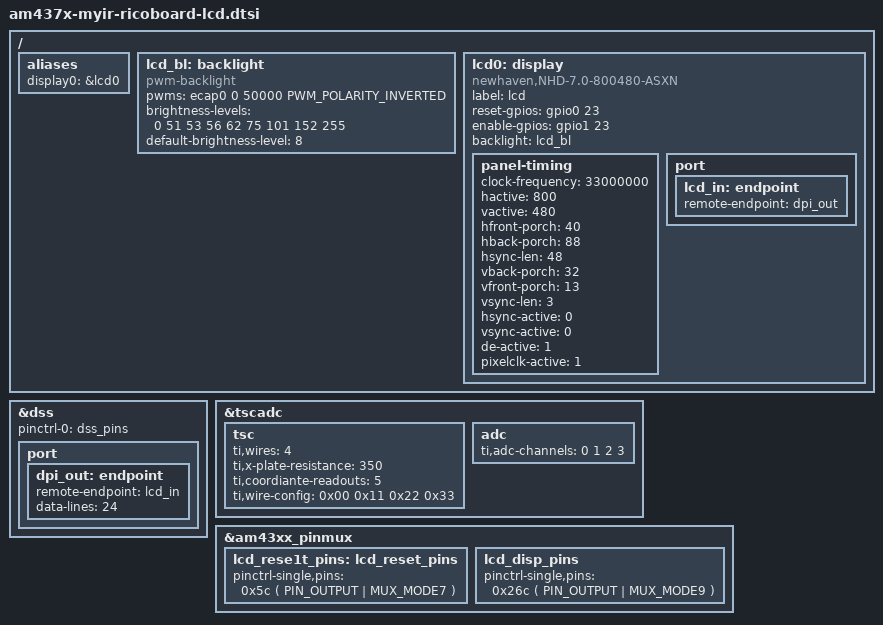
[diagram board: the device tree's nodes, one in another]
/*
 * Device Tree Source for am4378 Ricoboard
 *
 * Copyright (C) 2013 Texas Instruments Incorporated - http://www.ti.com/
 *
 * This file is licensed under the terms of the GNU General Public License
 * version 2.  This program is licensed "as is" without any warranty of any
 * kind, whether express or implied.
 */

/ {
	aliases {
		display0 = &lcd0;
	};
	
	lcd_bl: backlight {
		compatible = "pwm-backlight";
		pwms = <&ecap0 0 50000 PWM_POLARITY_INVERTED>;
		brightness-levels = <0 51 53 56 62 75 101 152 255>;
		default-brightness-level = <8>;
	};

	lcd0: display {
		compatible = "newhaven,NHD-7.0-800480-ASXN", "panel-dpi";
		label = "lcd";

		reset-gpios = <&gpio0 23 GPIO_ACTIVE_HIGH>;
		enable-gpios = <&gpio1 23 GPIO_ACTIVE_HIGH>;

		backlight = <&lcd_bl>;

		panel-timing {
			clock-frequency = <33000000>;
			hactive = <800>;
			vactive = <480>;
			hfront-porch = <40>;
			hback-porch = <88>;
			hsync-len = <48>;
			vback-porch = <32>;
			vfront-porch = <13>;
			vsync-len = <3>;
			hsync-active = <0>;
			vsync-active = <0>;
			de-active = <1>;
			pixelclk-active = <1>;
		};

		port {
			lcd_in: endpoint {
				remote-endpoint = <&dpi_out>;
			};
		};
	};
};

&dss {
	status = "ok";

	pinctrl-names = "default";
	pinctrl-0 = <&dss_pins>;

	port {
		dpi_out: endpoint {
			remote-endpoint = <&lcd_in>;
			data-lines = <24>;
		};
	};
};

&tscadc {
	status = "okay";
	tsc {
		ti,wires = <4>;
		ti,x-plate-resistance = <350>;
		ti,coordiante-readouts = <5>;
		ti,wire-config = <0x00 0x11 0x22 0x33>;
	};

	adc {
		ti,adc-channels = <0 1 2 3>;
	};
};

&am43xx_pinmux {
    lcd_rese1t_pins: lcd_reset_pins {
        pinctrl-single,pins = <
            0x5c ( PIN_OUTPUT | MUX_MODE7 ) /* (F6) gpmc_a7.gpio1[23] */
        >;
    };

    lcd_disp_pins: lcd_disp_pins {
        pinctrl-single,pins = <
            0x26c ( PIN_OUTPUT | MUX_MODE9 ) /* (T23) spi2_cs0.gpio0[23] */
        >;
    };
};
